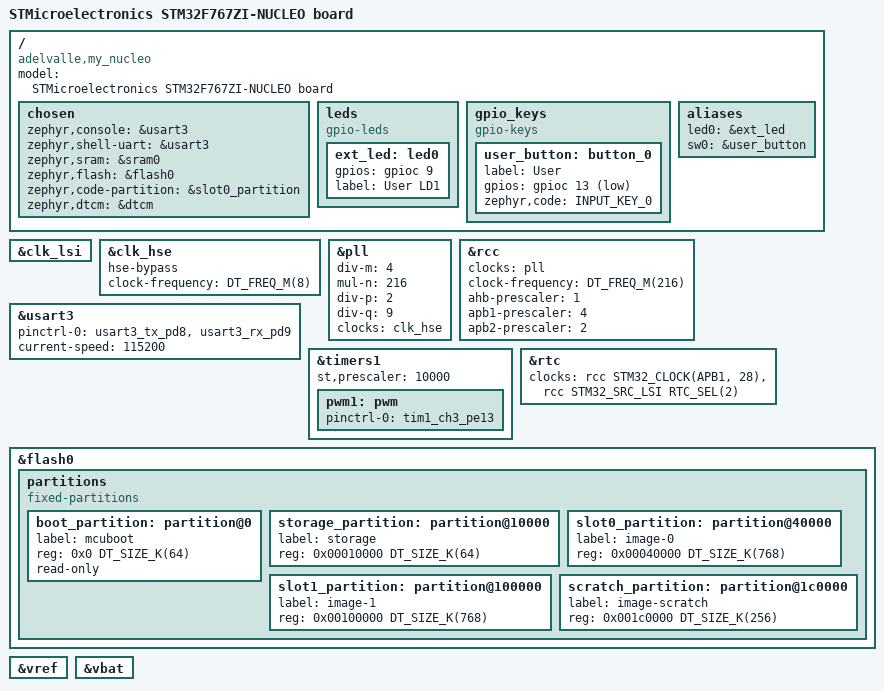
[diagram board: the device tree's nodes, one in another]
/*
 * Copyright (c) 2026 Angel del Valle
 *
 * SPDX-License-Identifier: Apache-2.0
 */

/dts-v1/;
#include <st/f7/stm32f767Xi.dtsi>
#include <st/f7/stm32f767zitx-pinctrl.dtsi>

/ {
	model = "STMicroelectronics STM32F767ZI-NUCLEO board";
	compatible = "adelvalle,my_nucleo";
    
    chosen {
        zephyr,console = &usart3;
		zephyr,shell-uart = &usart3;
        zephyr,sram = &sram0;
		zephyr,flash = &flash0;
		zephyr,code-partition = &slot0_partition;
        zephyr,dtcm = &dtcm;
    };

    leds: leds {
        compatible = "gpio-leds";

        ext_led: led0 {
            gpios = <&gpioc 9 GPIO_ACTIVE_HIGH>;
            label = "User LD1";
        };
    };

    gpio_keys {
		compatible = "gpio-keys";

		user_button: button_0 {
			label = "User";
			gpios = <&gpioc 13 GPIO_ACTIVE_LOW>;
			zephyr,code = <INPUT_KEY_0>;
		};
	};

    aliases {
        led0 = &ext_led;
        sw0 = &user_button;
    };
};

&clk_lsi {
	status = "okay";
};

&clk_hse {
    hse-bypass;
    clock-frequency = <DT_FREQ_M(8)>; /* STLink 8MHz clock */
    status = "okay";
};

&pll {
    div-m = <4>;
    mul-n = <216>;
    div-p = <2>;
    div-q = <9>;
    clocks = <&clk_hse>;
    status = "okay";
};

&rcc {
	clocks = <&pll>;
	clock-frequency = <DT_FREQ_M(216)>;
	ahb-prescaler = <1>;
	apb1-prescaler = <4>;
	apb2-prescaler = <2>;
};

&usart3 {
	pinctrl-0 = <&usart3_tx_pd8 &usart3_rx_pd9>;
	pinctrl-names = "default";
	current-speed = <115200>;
	status = "okay";
};

&timers1 {
	st,prescaler = <10000>;
	status = "okay";

	pwm1: pwm {
		status = "okay";
		pinctrl-0 = <&tim1_ch3_pe13>;
		pinctrl-names = "default";
	};
};

&rtc {
	clocks = <&rcc STM32_CLOCK(APB1, 28)>,
		 <&rcc STM32_SRC_LSI RTC_SEL(2)>;
	status = "okay";
};

&flash0 {
	partitions {
		compatible = "fixed-partitions";
		#address-cells = <1>;
		#size-cells = <1>;

		/*
		 * The two sectors 0-1 (32+32 kbytes) are reserved for
		 * the bootloader.
		 */
		boot_partition: partition@0 {
			label = "mcuboot";
			reg = <0x0 DT_SIZE_K(64)>;
			read-only;
		};

		/*
		 * The flash starting at offset 0x10000 and ending at
		 * offset 0x1ffff is reserved for use by the application.
		 * This represents sectors 2-3 (32+32 kbytes)
		 */
		storage_partition: partition@10000 {
			label = "storage";
			reg = <0x00010000 DT_SIZE_K(64)>;
		};

		/*
		 * Sector 4 (128 kbytes) unallocated.
		 */

		/*
		 * Allocated 3 (256k x 3) sectors for image-0. Sectors 5-7.
		 */
		slot0_partition: partition@40000 {
			label = "image-0";
			reg = <0x00040000 DT_SIZE_K(768)>;
		};

		/*
		 * Allocated 3 (256k x 3) sectors for image-1. Sectors 8-10.
		 */
		slot1_partition: partition@100000 {
			label = "image-1";
			reg = <0x00100000 DT_SIZE_K(768)>;
		};

		/*
		 * Allocated 1 (256k) sector for image-scratch. Sector 11.
		 */
		scratch_partition: partition@1c0000 {
			label = "image-scratch";
			reg = <0x001c0000 DT_SIZE_K(256)>;
		};
	};
};

&vref {
	status = "okay";
};

&vbat {
	status = "okay";
};
